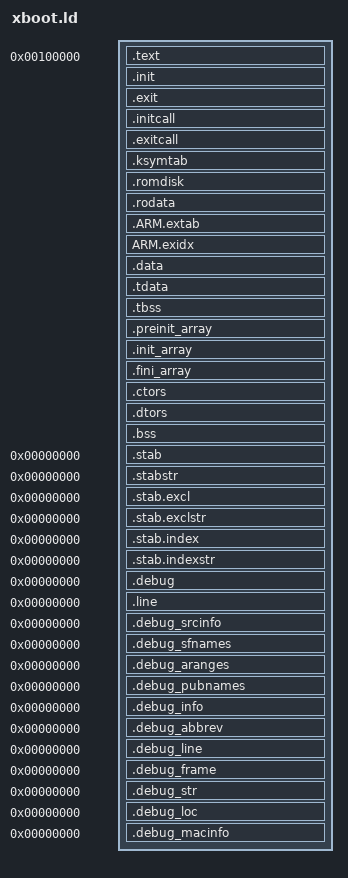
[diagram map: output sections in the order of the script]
OUTPUT_FORMAT("elf32-littlearm", "elf32-bigarm", "elf32-littlearm")
OUTPUT_ARCH(arm)
ENTRY(_start)

PHDRS
{
	code   PT_LOAD FLAGS(5) /* Read | Execute */;
	rodata PT_LOAD FLAGS(4) /* Read */;
	data   PT_LOAD FLAGS(6) /* Read | Write */;
}

SECTIONS
{
	/* =========== CODE section =========== */

	PROVIDE(__start__ = 0x100000);
	. = __start__;

	.text ALIGN(0x1000) :
	{
		/* .init */
		KEEP( *(.crt0) )
		KEEP( *(.init) )
		. = ALIGN(4);

		/* .text */
		*(.text)
		*(.text.*)
		*(.glue_7)
		*(.glue_7t)
		*(.stub)
		*(.gnu.warning)
		*(.gnu.linkonce.t*)
		. = ALIGN(4);

		/* .fini */
		KEEP( *(.fini) )
		. = ALIGN(4);
	} : code

	.init ALIGN(8) :
	{
		PROVIDE(__init_start = .);
		KEEP(*(.init.text))
		PROVIDE(__init_end = .);
	}

	.exit ALIGN(8) :
	{
		PROVIDE(__exit_start = .);
		KEEP(*(.exit.text))
		PROVIDE(__exit_end = .);
	}

	.initcall ALIGN(8) :
	{
		PROVIDE(__initcall_start = .);
		KEEP(*(.initcall_0.text))
		KEEP(*(.initcall_1.text))
		KEEP(*(.initcall_2.text))
		KEEP(*(.initcall_3.text))
		KEEP(*(.initcall_4.text))
		KEEP(*(.initcall_5.text))
		KEEP(*(.initcall_6.text))
		KEEP(*(.initcall_7.text))
		KEEP(*(.initcall_8.text))
		KEEP(*(.initcall_9.text))
		PROVIDE(__initcall_end = .);
	}

	.exitcall ALIGN(8) :
	{
		PROVIDE(__exitcall_start = .);
		KEEP(*(.exitcall_9.text))
		KEEP(*(.exitcall_8.text))
		KEEP(*(.exitcall_7.text))
		KEEP(*(.exitcall_6.text))
		KEEP(*(.exitcall_5.text))
		KEEP(*(.exitcall_4.text))
		KEEP(*(.exitcall_3.text))
		KEEP(*(.exitcall_2.text))
		KEEP(*(.exitcall_1.text))
		KEEP(*(.exitcall_0.text))
		PROVIDE(__exitcall_end = .);
	}

	.ksymtab ALIGN(16) :
	{
		PROVIDE(__ksymtab_start = .);
		KEEP(*(.ksymtab.text))
		PROVIDE(__ksymtab_end = .);
	}

	.romdisk ALIGN(8) :
	{
		PROVIDE(__romdisk_start = .);
		KEEP(*(.romdisk))
		PROVIDE(__romdisk_end = .);
	}

	/* =========== RODATA section =========== */

	. = ALIGN(0x1000);

	.rodata :
	{
		*(.rodata)
		*(.roda)
		*(.rodata.*)
		*all.rodata*(*)
		*(.gnu.linkonce.r*)
		SORT(CONSTRUCTORS)
		. = ALIGN(4);
	} : rodata

	.ARM.extab : { *(.ARM.extab* .gnu.linkonce.armextab.*) } : rodata
	__exidx_start = .;
	ARM.exidx : { *(.ARM.exidx* .gnu.linkonce.armexidx.*) } : rodata
	__exidx_end = .;

	/* =========== DATA section =========== */

	. = ALIGN(0x1000);

	.data :
	{
		*(.data)
		*(.data.*)
		*(.gnu.linkonce.d*)
		CONSTRUCTORS
		. = ALIGN(4);
	} : data

	.tdata ALIGN(4) :
	{
		__tdata_lma = .;
		*(.tdata)
		*(.tdata.*)
		*(.gnu.linkonce.td.*)
		. = ALIGN(4);
		__tdata_lma_end = .;
	} : data

	.tbss ALIGN(4) :
	{
		*(.tbss)
		*(.tbss.*)
		*(.gnu.linkonce.tb.*)
		*(.tcommon)
		. = ALIGN(4);
	} : data

	.preinit_array ALIGN(4) :
	{
		PROVIDE (__preinit_array_start = .);
		KEEP (*(.preinit_array))
		PROVIDE (__preinit_array_end = .);
	} : data

	.init_array ALIGN(4) :
	{
		PROVIDE (__init_array_start = .);
		KEEP (*(SORT(.init_array.*)))
		KEEP (*(.init_array))
		PROVIDE (__init_array_end = .);
	} : data

	.fini_array ALIGN(4) :
	{
		PROVIDE (__fini_array_start = .);
		KEEP (*(.fini_array))
		KEEP (*(SORT(.fini_array.*)))
		PROVIDE (__fini_array_end = .);
	} : data

	.ctors ALIGN(4) :
	{
		KEEP (*crtbegin.o(.ctors)) /* MUST be first -- GCC requires it */
		KEEP (*(EXCLUDE_FILE (*crtend.o) .ctors))
		KEEP (*(SORT(.ctors.*)))
		KEEP (*(.ctors))
	} : data

	.dtors ALIGN(4) :
	{
		KEEP (*crtbegin.o(.dtors))
		KEEP (*(EXCLUDE_FILE (*crtend.o) .dtors))
		KEEP (*(SORT(.dtors.*)))
		KEEP (*(.dtors))
	} : data

	__bss_start__ = .;
	.bss ALIGN(4) :
	{
		*(.dynbss)
		*(.bss)
		*(.bss.*)
		*(.gnu.linkonce.b*)
		*(COMMON)
		. = ALIGN(4);

		/* Reserve space for the TLS segment of the main thread */
		__tls_start = .;
		. += + SIZEOF(.tdata) + SIZEOF(.tbss);
		__tls_end = .;
	} : data
	__bss_end__ = .;

	__end__ = ABSOLUTE(.) ;

	/* ==================
	   ==== Metadata ====
	   ================== */

	/* Discard sections that difficult post-processing */
	/DISCARD/ : { *(.group .comment .note) }

	/* Stabs debugging sections. */
	.stab          0 : { *(.stab) }
	.stabstr       0 : { *(.stabstr) }
	.stab.excl     0 : { *(.stab.excl) }
	.stab.exclstr  0 : { *(.stab.exclstr) }
	.stab.index    0 : { *(.stab.index) }
	.stab.indexstr 0 : { *(.stab.indexstr) }

	/* DWARF debug sections.
	   Symbols in the DWARF debugging sections are relative to the beginning
	   of the section so we begin them at 0. */

	/* DWARF 1 */
	.debug          0 : { *(.debug) }
	.line           0 : { *(.line) }

	/* GNU DWARF 1 extensions */
	.debug_srcinfo  0 : { *(.debug_srcinfo) }
	.debug_sfnames  0 : { *(.debug_sfnames) }

	/* DWARF 1.1 and DWARF 2 */
	.debug_aranges  0 : { *(.debug_aranges) }
	.debug_pubnames 0 : { *(.debug_pubnames) }

	/* DWARF 2 */
	.debug_info     0 : { *(.debug_info) }
	.debug_abbrev   0 : { *(.debug_abbrev) }
	.debug_line     0 : { *(.debug_line) }
	.debug_frame    0 : { *(.debug_frame) }
	.debug_str      0 : { *(.debug_str) }
	.debug_loc      0 : { *(.debug_loc) }
	.debug_macinfo  0 : { *(.debug_macinfo) }
}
